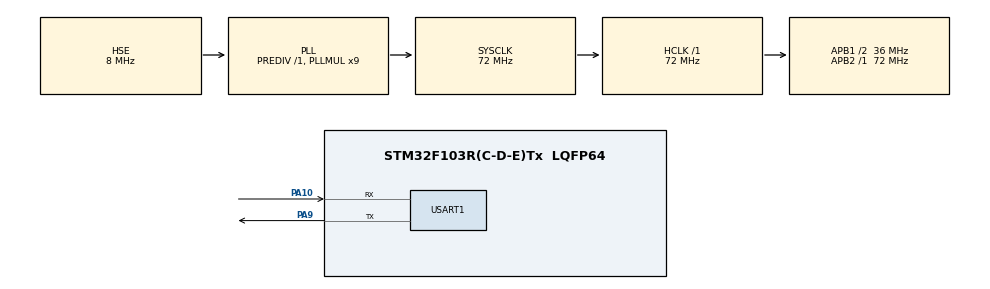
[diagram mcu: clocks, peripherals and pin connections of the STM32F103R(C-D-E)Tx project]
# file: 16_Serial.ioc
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Dma.Request0=USART1_RX
Dma.Request1=USART1_TX
Dma.USART1_RX.0.Direction=DMA_PERIPH_TO_MEMORY
Dma.USART1_RX.0.Instance=DMA1_Channel5
Dma.USART1_RX.0.MemDataAlignment=DMA_MDATAALIGN_BYTE
Dma.USART1_RX.0.MemInc=DMA_MINC_ENABLE
Dma.USART1_RX.0.Mode=DMA_NORMAL
Dma.USART1_RX.0.PeriphDataAlignment=DMA_PDATAALIGN_BYTE
Dma.USART1_RX.0.PeriphInc=DMA_PINC_DISABLE
Dma.USART1_RX.0.Priority=DMA_PRIORITY_LOW
Dma.USART1_TX.1.Direction=DMA_MEMORY_TO_PERIPH
Dma.USART1_TX.1.Instance=DMA1_Channel4
Dma.USART1_TX.1.MemDataAlignment=DMA_MDATAALIGN_BYTE
Dma.USART1_TX.1.MemInc=DMA_MINC_ENABLE
Dma.USART1_TX.1.Mode=DMA_NORMAL
Dma.USART1_TX.1.PeriphDataAlignment=DMA_PDATAALIGN_BYTE
Dma.USART1_TX.1.PeriphInc=DMA_PINC_DISABLE
Dma.USART1_TX.1.Priority=DMA_PRIORITY_LOW
FREERTOS.Tasks01=Serial,24,256,Serial_Entry,Default,NULL,Dynamic,NULL,NULL
Mcu.Family=STM32F1
Mcu.Name=STM32F103R(C-D-E)Tx
Mcu.Package=LQFP64
NVIC.DMA1_Channel4_IRQn=true\:5\:0\:false\:false\:true\:true\:false\:true\:true
NVIC.DMA1_Channel5_IRQn=true\:5\:0\:false\:false\:true\:true\:false\:true\:true
NVIC.PriorityGroup=NVIC_PRIORITYGROUP_4
NVIC.TIM7_IRQn=true\:15\:0\:false\:false\:true\:false\:false\:true\:true
NVIC.TimeBase=TIM7_IRQn
NVIC.TimeBaseIP=TIM7
NVIC.USART1_IRQn=true\:5\:0\:false\:false\:true\:true\:true\:true\:true
PA10.Mode=Asynchronous
PA10.Signal=USART1_RX
PA13.Mode=Serial_Wire
PA13.Signal=SYS_JTMS-SWDIO
PA14.Mode=Serial_Wire
PA14.Signal=SYS_JTCK-SWCLK
PA9.Mode=Asynchronous
PA9.Signal=USART1_TX
PC14-OSC32_IN.Mode=LSE-External-Oscillator
PC14-OSC32_IN.Signal=RCC_OSC32_IN
PC15-OSC32_OUT.Mode=LSE-External-Oscillator
PC15-OSC32_OUT.Signal=RCC_OSC32_OUT
PD0-OSC_IN.Mode=HSE-External-Oscillator
PD0-OSC_IN.Signal=RCC_OSC_IN
PD1-OSC_OUT.Mode=HSE-External-Oscillator
PD1-OSC_OUT.Signal=RCC_OSC_OUT
ProjectManager.HeapSize=0x200
ProjectManager.StackSize=0x400
ProjectManager.TargetToolchain=MDK-ARM V5.32
RCC.AHBFreq_Value=72000000
RCC.APB1CLKDivider=RCC_HCLK_DIV2
RCC.APB1Freq_Value=36000000
RCC.APB1TimFreq_Value=72000000
RCC.APB2Freq_Value=72000000
RCC.APB2TimFreq_Value=72000000
RCC.HCLKFreq_Value=72000000
RCC.PLLMUL=RCC_PLL_MUL9
RCC.PLLSourceVirtual=RCC_PLLSOURCE_HSE
RCC.SYSCLKFreq_VALUE=72000000
RCC.SYSCLKSource=RCC_SYSCLKSOURCE_PLLCLK
RCC.USBFreq_Value=72000000
USART1.VirtualMode=VM_ASYNC
VP_FREERTOS_VS_CMSIS_V2.Mode=CMSIS_V2
VP_SYS_VS_tim7.Mode=TIM7
board=custom

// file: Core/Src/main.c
/* USER CODE BEGIN Header */
/**
  ******************************************************************************
  * @file           : main.c
  * @brief          : Main program body
  ******************************************************************************
  * @attention
  *
  * Copyright (c) 2024 STMicroelectronics.
  * All rights reserved.
  *
  * This software is licensed under terms that can be found in the LICENSE file
  * in the root directory of this software component.
  * If no LICENSE file comes with this software, it is provided AS-IS.
  *
  ******************************************************************************
  */
/* USER CODE END Header */
#include "main.h"
#include "cmsis_os.h"
#include "dma.h"
#include "usart.h"
#include "gpio.h"

void SystemClock_Config(void);
void MX_FREERTOS_Init(void);

int main(void)
{

  /* MCU Configuration--------------------------------------------------------*/

  /* Reset of all peripherals, Initializes the Flash interface and the Systick. */
  HAL_Init();

  /* Configure the system clock */
  SystemClock_Config();

  /* Initialize all configured peripherals */
  MX_GPIO_Init();
  MX_DMA_Init();
  MX_USART1_UART_Init();

  /* Init scheduler */
  osKernelInitialize();

  /* Call init function for freertos objects (in freertos.c) */
  MX_FREERTOS_Init();

  /* Start scheduler */
  osKernelStart();

  /* We should never get here as control is now taken by the scheduler */
  /* Infinite loop */
  while (1)
  {

  }
}

void SystemClock_Config(void)
{
  RCC_OscInitTypeDef RCC_OscInitStruct = {0};
  RCC_ClkInitTypeDef RCC_ClkInitStruct = {0};

  /** Initializes the RCC Oscillators according to the specified parameters
  * in the RCC_OscInitTypeDef structure.
  */
  RCC_OscInitStruct.OscillatorType = RCC_OSCILLATORTYPE_HSE;
  RCC_OscInitStruct.HSEState = RCC_HSE_ON;
  RCC_OscInitStruct.HSEPredivValue = RCC_HSE_PREDIV_DIV1;
  RCC_OscInitStruct.HSIState = RCC_HSI_ON;
  RCC_OscInitStruct.PLL.PLLState = RCC_PLL_ON;
  RCC_OscInitStruct.PLL.PLLSource = RCC_PLLSOURCE_HSE;
  RCC_OscInitStruct.PLL.PLLMUL = RCC_PLL_MUL9;
  if (HAL_RCC_OscConfig(&RCC_OscInitStruct) != HAL_OK)
  {
    Error_Handler();
  }

  /** Initializes the CPU, AHB and APB buses clocks
  */
  RCC_ClkInitStruct.ClockType = RCC_CLOCKTYPE_HCLK|RCC_CLOCKTYPE_SYSCLK
                              |RCC_CLOCKTYPE_PCLK1|RCC_CLOCKTYPE_PCLK2;
  RCC_ClkInitStruct.SYSCLKSource = RCC_SYSCLKSOURCE_PLLCLK;
  RCC_ClkInitStruct.AHBCLKDivider = RCC_SYSCLK_DIV1;
  RCC_ClkInitStruct.APB1CLKDivider = RCC_HCLK_DIV2;
  RCC_ClkInitStruct.APB2CLKDivider = RCC_HCLK_DIV1;

  if (HAL_RCC_ClockConfig(&RCC_ClkInitStruct, FLASH_LATENCY_2) != HAL_OK)
  {
    Error_Handler();
  }
}

void HAL_TIM_PeriodElapsedCallback(TIM_HandleTypeDef *htim)
{
  if (htim->Instance == TIM7) {
    HAL_IncTick();
  }
}

void Error_Handler(void)
{
  __disable_irq();
  while (1)
  {
  }
}

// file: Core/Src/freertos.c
/* USER CODE BEGIN Header */
/**
  ******************************************************************************
  * File Name          : freertos.c
  * Description        : Code for freertos applications
  ******************************************************************************
  * @attention
  *
  * Copyright (c) 2024 STMicroelectronics.
  * All rights reserved.
  *
  * This software is licensed under terms that can be found in the LICENSE file
  * in the root directory of this software component.
  * If no LICENSE file comes with this software, it is provided AS-IS.
  *
  ******************************************************************************
  */
/* USER CODE END Header */

#include "FreeRTOS.h"
#include "task.h"
#include "main.h"
#include "cmsis_os.h"

/* USER CODE BEGIN Includes */
#include "usart.h"
#include "stdio.h"
#include "stdlib.h"
#include "string.h"
/* USER CODE END Includes */

/* USER CODE BEGIN Variables */
#define rxBufferLen 40 // 接收数据的最大长度
#define __HAL_DMA_SET_COUNTER(__HANDLE__, __COUNTER__) ((__HANDLE__)->Instance->CNDTR = (uint16_t)(__COUNTER__))
char rxBuffer[rxBufferLen]; // 用于存放接收到的数据
/* USER CODE END Variables */
/* Definitions for Serial */
osThreadId_t SerialHandle;
const osThreadAttr_t Serial_attributes = {
  .name = "Serial",
  .stack_size = 256 * 4,
  .priority = (osPriority_t) osPriorityNormal,
};

void Serial_Entry(void *argument);

void MX_FREERTOS_Init(void); /* (MISRA C 2004 rule 8.1) */

void MX_FREERTOS_Init(void) {

  /* Create the thread(s) */
  /* creation of Serial */
  SerialHandle = osThreadNew(Serial_Entry, NULL, &Serial_attributes);

}

void Serial_Entry(void *argument)
{
  /* USER CODE BEGIN Serial_Entry */
  __HAL_UART_CLEAR_IDLEFLAG(&huart1); // 清除空闲中断标志位
  __HAL_UART_ENABLE_IT(&huart1, UART_IT_IDLE); // 开启UART的空闲中断
  HAL_UART_Receive_DMA(&huart1, (uint8_t*)rxBuffer, rxBufferLen ); // 启动DMA接收
  uint8_t TXbuff[] = "\r\n**** UART-Hyperterminal communication based on DMA ***\r\n ";
  /* Infinite loop */
  for(;;)
  {
	//HAL_UART_Transmit_DMA(&huart1, (uint8_t *)TXbuff, sizeof(TXbuff)-1);
    osDelay(1000);
  }
  /* USER CODE END Serial_Entry */
}

/* USER CODE BEGIN Application */
void HAL_UART_TxCpltCallback(UART_HandleTypeDef *huart)
{
    // if(huart->Instance == USART1)
    // {
    //     HAL_UART_Receive_DMA(&huart1, &rxData[0], sizeof(rxData));
    // }
}

void HAL_UART_RxCpltCallback(UART_HandleTypeDef *huart)
{
    // if(huart->Instance == USART1)
    // {
    //     HAL_UART_Transmit_DMA(&huart1, &rxData[0], sizeof(rxData));
    //     HAL_UART_Receive_DMA(&huart1, &rxData[0], sizeof(rxData));
    // }
}

void UART_DMAIdleCallback(UART_HandleTypeDef *huart)
{
    if(huart == &huart1)
    {
        // 停止DMA接收
        __HAL_DMA_DISABLE(huart->hdmarx);
        // 计算接收到的数据长度
        uint8_t dataLen = rxBufferLen - __HAL_DMA_GET_COUNTER(huart->hdmarx) + '0';
        // 发送数据长度，使用轮询方法
        HAL_UART_Transmit_DMA(&huart1, (uint8_t*)rxBuffer, rxBufferLen);

        // 重启DMA接收
        __HAL_DMA_SET_COUNTER(huart->hdmarx, rxBufferLen); // 重设DMA计数器
        __HAL_DMA_ENABLE(huart->hdmarx); // 使能DMA接收
    }
}

int fputc(int ch, FILE *f)
{
    HAL_UART_Transmit(&huart1, (uint8_t *)&ch, 1, 0xFFFF);
    return ch;
}
/* USER CODE END Application */
